AUTOSAR XML (schema 00046)
package /ComponentTypes
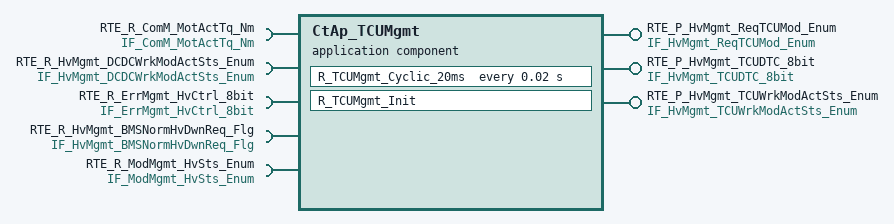
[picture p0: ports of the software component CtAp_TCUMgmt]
  application sw component type CtAp_TCUMgmt
    provide port RTE_P_HvMgmt_ReqTCUMod_Enum: nonqueued-sender-com-spec{data-element=tec_HvMgmt_ReqTCUMod_Enum, init-value=0}, provided-interface=IF_HvMgmt_ReqTCUMod_Enum
    provide port RTE_P_HvMgmt_TCUDTC_8bit: nonqueued-sender-com-spec{data-element=tec_HvMgmt_TCUDTC_8bit, init-value=0}, provided-interface=IF_HvMgmt_TCUDTC_8bit
    5 x require port:
      RTE_R_ComM_MotActTq_Nm: nonqueued-receiver-com-spec{data-element=tec_ComM_MotActTq_Nm, filter=data-filter-type=ALWAYS, init-value=0}, required-interface=IF_ComM_MotActTq_Nm
      RTE_R_HvMgmt_DCDCWrkModActSts_Enum: nonqueued-receiver-com-spec{data-element=tec_HvMgmt_DCDCWrkModActSts_Enum, filter=data-filter-type=ALWAYS, init-value=0}, required-interface=IF_HvMgmt_DCDCWrkModActSts_Enum
      RTE_R_ErrMgmt_HvCtrl_8bit: nonqueued-receiver-com-spec{data-element=tec_ErrMgmt_HvCtrl_8bit, filter=data-filter-type=ALWAYS, init-value=0}, required-interface=IF_ErrMgmt_HvCtrl_8bit
      RTE_R_HvMgmt_BMSNormHvDwnReq_Flg: nonqueued-receiver-com-spec{data-element=tec_HvMgmt_BMSNormHvDwnReq_Flg, filter=data-filter-type=ALWAYS, init-value=0}, required-interface=IF_HvMgmt_BMSNormHvDwnReq_Flg
      RTE_R_ModMgmt_HvSts_Enum: nonqueued-receiver-com-spec{data-element=tec_ModMgmt_HvSts_Enum, filter=data-filter-type=ALWAYS, init-value=0}, required-interface=IF_ModMgmt_HvSts_Enum
    provide port RTE_P_HvMgmt_TCUWrkModActSts_Enum: nonqueued-sender-com-spec{data-element=tec_HvMgmt_TCUWrkModActSts_Enum, init-value=0}, provided-interface=IF_HvMgmt_TCUWrkModActSts_Enum
    behavior CtAp_TCUMgmt_InternalBehavior
      init event CtAp_TCUMgmt_InitEvent: start-on-event=R_TCUMgmt_Init
      timing event TMT_R_TCUMgmt_Cyclic_20ms: start-on-event=R_TCUMgmt_Cyclic_20ms, period=0.02
      runnable R_TCUMgmt_Init
      runnable R_TCUMgmt_Cyclic_20ms
        data-receive-point-by-arguments:
          5 x access:
            REC_RTE_R_ComM_MotActTq_Nm_tec_ComM_MotActTq_Nm: accessed-variable=RTE_R_ComM_MotActTq_Nm.tec_ComM_MotActTq_Nm
            REC_RTE_R_ErrMgmt_HvCtrl_8bit_tec_ErrMgmt_HvCtrl_8bit: accessed-variable=RTE_R_ErrMgmt_HvCtrl_8bit.tec_ErrMgmt_HvCtrl_8bit
            REC_RTE_R_HvMgmt_BMSNormHvDwnReq_Flg_tec_HvMgmt_BMSNormHvDwnReq_Flg: accessed-variable=RTE_R_HvMgmt_BMSNormHvDwnReq_Flg.tec_HvMgmt_BMSNormHvDwnReq_Flg
            REC_RTE_R_HvMgmt_DCDCWrkModActSts_Enum_tec_HvMgmt_DCDCWrkModActSts_Enum: accessed-variable=RTE_R_HvMgmt_DCDCWrkModActSts_Enum.tec_HvMgmt_DCDCWrkModActSts_Enum
            REC_RTE_R_ModMgmt_HvSts_Enum_tec_ModMgmt_HvSts_Enum: accessed-variable=RTE_R_ModMgmt_HvSts_Enum.tec_ModMgmt_HvSts_Enum
        data-send-points:
          access SEND_RTE_P_HvMgmt_ReqTCUMod_Enum_tec_HvMgmt_ReqTCUMod_Enum: accessed-variable=RTE_P_HvMgmt_ReqTCUMod_Enum.tec_HvMgmt_ReqTCUMod_Enum
          access SEND_RTE_P_HvMgmt_TCUDTC_8bit_tec_HvMgmt_TCUDTC_8bit: accessed-variable=RTE_P_HvMgmt_TCUDTC_8bit.tec_HvMgmt_TCUDTC_8bit
          access SEND_RTE_P_HvMgmt_TCUWrkModActSts_Enum_tec_HvMgmt_TCUWrkModActSts_Enum: accessed-variable=RTE_P_HvMgmt_TCUWrkModActSts_Enum.tec_HvMgmt_TCUWrkModActSts_Enum
  swc implementation CtAp_TCUMgmt_Implementation: behavior=CtAp_TCUMgmt_InternalBehavior
    code-descriptors:
      code Default: artifact-descriptors=autosar-engineering-object=category=SWOBJ
